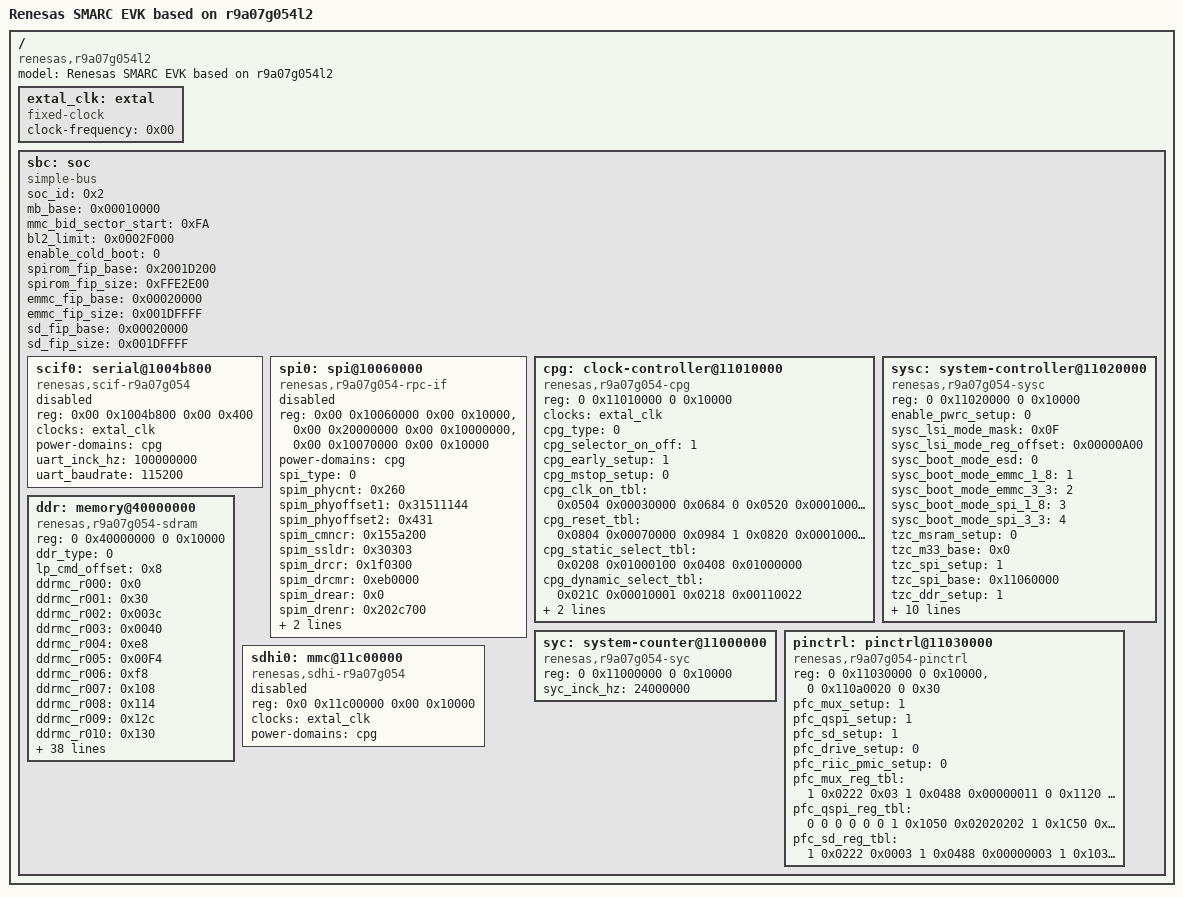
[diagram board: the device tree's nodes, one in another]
// SPDX-License-Identifier: (GPL-2.0-only OR BSD-2-Clause)
/*
 * Device Tree Source for the RZ/V2L SMARC EVK board
 *
 * Copyright (C) 2025 Renesas Electronics Corp.
 */

/dts-v1/;

/ {
	compatible = "renesas,r9a07g054l2", "renesas,r9a07g054";
	model = "Renesas SMARC EVK based on r9a07g054l2";
	#address-cells = <2>;
	#size-cells = <2>;

	/* clock can be either from exclk or crystal oscillator (XIN/XOUT) */
	extal_clk: extal {
		compatible = "fixed-clock";
		#clock-cells = <0x00>;
		clock-frequency = <0x00>;
		phandle = <0x03>;
	};

	sbc: soc {
		compatible = "simple-bus";
		soc_id = <0x2>;
		mb_base = <0x00010000>;
		mmc_bid_sector_start = <0xFA>;
		bl2_limit = <0x0002F000>;
		enable_cold_boot = <0>;
		spirom_fip_base = <0x2001D200>;
		spirom_fip_size = <0xFFE2E00>;
		emmc_fip_base = <0x00020000>;
		emmc_fip_size = <0x001DFFFF>;
		sd_fip_base = <0x00020000>;
		sd_fip_size = <0x001DFFFF>;
		#address-cells = <0x02>;
		#size-cells = <0x02>;
		ranges;

		scif0: serial@1004b800 {
			compatible = "renesas,scif-r9a07g054";
			reg = <0x00 0x1004b800 0x00 0x400>;
			interrupt-names = "eri", "rxi", "txi", "bri", "dri", "tei";
			clocks = <&extal_clk>;
			clock-names = "fck";
			power-domains = <&cpg>;
			status = "disabled";

			uart_inck_hz = <100000000>;
			uart_baudrate = <115200>;
		};

		spi0: spi@10060000 {
			compatible = "renesas,r9a07g054-rpc-if", "renesas,rzg2l-rpc-if";
			reg = <0x00 0x10060000 0x00 0x10000>,
			      <0x00 0x20000000 0x00 0x10000000>,
			      <0x00 0x10070000 0x00 0x10000>;
			reg-names = "regs", "dirmap", "wbuf";
			power-domains = <&cpg>;
			#address-cells = <1>;
			#size-cells = <0>;
			status = "disabled";

			/* SPI type
			 * [0] = SPI Multi IO
			 * [1] = XSPI
			 */
			spi_type = <0>;

			/* SPI Multi IO specific settings */
			spim_phycnt = <0x260>;
			spim_phyoffset1 = <0x31511144>;
			spim_phyoffset2 = <0x431>;
			spim_cmncr = <0x155a200>;
			spim_ssldr = <0x30303>;
			spim_drcr = <0x1f0300>;
			spim_drcmr = <0xeb0000>;
			spim_drear = <0x0>;
			spim_drenr = <0x202c700>;
			spim_drdmcr = <0x9>;
			spim_drdrenr = <0x0>;
		};

		cpg: clock-controller@11010000 {
			compatible = "renesas,r9a07g054-cpg";
			reg = <0 0x11010000 0 0x10000>;
			clocks = <&extal_clk>;
			clock-names = "extal";
			#clock-cells = <2>;
			#reset-cells = <1>;
			#power-domain-cells = <0>;

			cpg_type = <0>;
			cpg_selector_on_off = <1>;
			cpg_early_setup = <1>;
			cpg_mstop_setup = <0>;

			cpg_clk_on_tbl = <
				0x0504 0x00030000
				0x0684
				0

				0x0520 0x00010000
				0x06A0
				0

				0x052C 0x00030003
				0x06AC
				0

				0x0534 0x00060000
				0x06B4
				0

				0x0538 0x00010000
				0x06B8
				0

				0x053C 0x00010000
				0x06BC
				0

				0x0540 0x00010000
				0x06C0
				0

				0x0544 0x000F0000
				0x06C4
				0

				0x0548 0x003C0000
				0x06C8
				0


				0x054C 0x00030000
				0x06CC
				0

				0x0550 0x00030003
				0x06D0
				0

				0x0554 0x00ff00ff
				0x06D4
				0

				0x0558 0x00070000
				0x06D8
				0

				0x055C 0x00030000
				0x06DC
				0

				0x0560 0x00010001
				0x06E0
				0

				0x0564 0x001f0000
				0x06E4
				0

				0x0568 0x003f0000
				0x06E8
				0

				0x056C 0x00030000
				0x06EC
				0

				0x0570 0x00ff0000
				0x06F0
				0

				0x0574 0x00010000
				0x06F4
				0

				0x0578 0x000f0000
				0x06F8
				0

				0x057C 0x00030000
				0x06FC
				0

				0x0580 0x000f0000
				0x0700
				0

				0x0584 0x001f0001
				0x0704
				0

				0x0588 0x00030000
				0x0708
				0

				0x058C 0x00010000
				0x070C
				0

				0x0590 0x00070000
				0x0710
				0

				0x0594 0x00010000
				0x0714
				0

				0x0598 0x00010001
				0x0718
				0

				0x05A8 0x00030000
				0x0728
				0

				0x05AC 0x00010000
				0x072C
				0
			>;

			cpg_reset_tbl = <
				0x0804 0x00070000
				0x0984
				1

				0x0820 0x00010000
				0x09A0
				1

				0x082C 0x00030003
				0x09AC
				1

				0x0834 0x00060000
				0x09B4
				1

				0x0838 0x00010000
				0x09B8
				1

				0x083C 0x00010000
				0x09BC
				1

				0x0840 0x00010000
				0x09C0
				1

				0x0844 0x000f0000
				0x09C4
				1

				0x0848 0x00060000
				0x09C8
				1

				0x084C 0x007F0000
				0x09CC
				1

				0x0850 0x00010001
				0x09D0
				1

				0x0854 0x00030003
				0x09D4
				1

				0x0858 0x00070000
				0x09D8
				1

				0x085C 0x00030000
				0x09DC
				1

				0x0860 0x00030003
				0x09E0
				1

				0x0864 0x00070000
				0x09E4
				1

				0x0868 0x00070000
				0x09E8
				1

				0x086C 0x00010000
				0x09EC
				1

				0x0870 0x000f0000
				0x09F0
				1

				0x0874 0x00010000
				0x09F4
				1

				0x0878 0x000f0000
				0x09F8
				1

				0x087C 0x00030000
				0x09FC
				1

				0x0880 0x000f0000
				0x0A00
				1

				0x0884 0x001f0001
				0x0A04
				1

				0x0888 0x00030000
				0x0A08
				1

				0x088C 0x00010000
				0x0A0C
				1

				0x0890 0x00070000
				0x0A10
				1

				0x0894 0x00030000
				0x0A14
				1

				0x0898 0x00070007
				0x0A18
				1

				0x08A8 0x00030000
				0x0A28
				1

				0x08AC 0x00010000
				0x0A2C
				1
			>;

			cpg_static_select_tbl = <
				0x0208 0x01000100
				0x0408 0x01000000
			>;

			cpg_dynamic_select_tbl = <
				0x021C 0x00010001
				0x0218 0x00110022
			>;

			cpg_pll_tbl = <
				0x0010 0x00010001
				0x0014 0xFAE13203
				0x0018 0x00081000
				0x001C 0x00000011

				0x0020 0x00010001
				0x0024 0x00003e83
				0x0028 0x00082D02
				0x002C 0x00000011
			>;
		};

		sysc: system-controller@11020000 {
			compatible = "renesas,r9a07g054-sysc";
			reg = <0 0x11020000 0 0x10000>;

			enable_pwrc_setup					= <0>;
			sysc_lsi_mode_mask 			= <0x0F>;
			sysc_lsi_mode_reg_offset	= <0x00000A00>;
			sysc_boot_mode_esd 			= <0>;
			sysc_boot_mode_emmc_1_8 	= <1>;
			sysc_boot_mode_emmc_3_3 	= <2>;
			sysc_boot_mode_spi_1_8 		= <3>;
			sysc_boot_mode_spi_3_3 		= <4>;

			/* Security control. */
			tzc_msram_setup = <0>;
			tzc_m33_base	= <0x0>;	// Not used
			tzc_spi_setup	= <1>;
			tzc_spi_base	= <0x11060000>;
			tzc_ddr_setup	= <1>;
			tzc_ddr00_base	= <0x11070000>;
			tzc_ddr01_base	= <0x0>;	// Not used
			tzc_ddr10_base	= <0x0>;	// Not used
			tzc_ddr11_base	= <0x0>;	// Not used
			tzc_pci_setup	= <0>;
			tzc_pci_base	= <0x0>;	// Not used
			tzc_r8_setup	= <0>;
			tzc_r8_base		= <0x0>;	// Not used

			sys_acctl = <
				0x00000000 0x00BB00BB 0x00AAAA88
				0x00000004 0xBBBBBBBB 0xAAAAAAAA
				0x00000008 0x00BBBBBB 0x00AAAAAA
				0x0000000C 0x00BBBBBB 0x00AAAAAA
				0x00000010 0x0B0B00BB 0x0A0A00AA
				0x00000014 0x00000000 0x00000000
				0x00000100 0x0000000F 0x00000008
				0x00000104 0x3FFF3CFF 0x0800C0AA
				0x00000108 0x00FFCFFF 0x00000002
				0x0000010C 0x3FFF3FFF 0x00000000
				0x00000110 0xFFFF0FFF 0x00000000
				0x00000114 0x00000033 0x00000000
				0x00000118 0x0000000F 0x00000000
				0x0000011C 0x0000000C 0x00000008
				0x00000120 0x0000000F 0x00000000
				0x00000124 0x00000000 0x00000000
				0x00000128 0x00000003 0x00000000
				0x0000012C 0x00000000 0x00000000
				0x00000130 0x00000003 0x00000000
				0x00000134 0x00000003 0x00000000
				0x00000138 0x00000003 0x00000000
				0x0000013C 0x00000000 0x00000000
			>;
		};

		syc: system-counter@11000000 {
			compatible = "renesas,r9a07g054-syc";
			reg = <0 0x11000000 0 0x10000>;

			syc_inck_hz = <24000000>;
		};

		pinctrl: pinctrl@11030000 {
			compatible = "renesas,r9a07g054-pinctrl";
			reg = <0 0x11030000 0 0x10000>, <0 0x110a0020 0 0x30>;

			pfc_mux_setup		= <1>;
			pfc_qspi_setup		= <1>;
			pfc_sd_setup		= <1>;
			pfc_drive_setup		= <0>;
			pfc_riic_pmic_setup	= <0>;

			pfc_mux_reg_tbl = <
				1 0x0222 0x03
				1 0x0488 0x00000011
				0 0x1120 0x00000101
				0 0x1D10 0x00000000
				0 0x1510 0x00000101

				1 0x0223 0x03
				1 0x048C 0x00000011
				0 0x1128 0x00000101
				0 0x1D18 0x00000000
				0 0x1518 0x00000101

				1 0x0236 0x03
				1 0x04D8 0x00000011
				0 0x11B0 0x00000101
				0 0x1DB0 0x00000000
				0 0x15B0 0x00000101

				1 0x0237 0x07
				1 0x04DC 0x00000111
				0 0x11B8 0x00010101
				0 0x1DB8 0x00000000
				0 0x15B8 0x00010101
			>;

			pfc_qspi_reg_tbl = <
				0 0 0
				0 0 0
				1 0x1050 0x02020202
				1 0x1C50 0x00000000
				1 0x1450 0x01010101

				0 0 0
				0 0 0
				1 0x1058 0x02020202
				1 0x1C58 0x00000000
				1 0x1458 0x01010101

				0 0 0
				0 0 0
				1 0x1060 0x00020202
				1 0x1C60 0x00000000
				1 0x1460 0x00010000
			>;

			pfc_sd_reg_tbl = <
				1 0x0222 0x0003
				1 0x0488 0x00000003
				1 0x1030 0x00020202
				1 0x1C30 0x00000000
				1 0x1430 0x00010101
				1 0x1830 0x00000100

				0 0 0
				0 0 0
				1 0x1038 0x02020202
				1 0x1C38 0x00000000
				1 0x1438 0x01010101
				1 0x1838 0x01010101

				1 0x0223 0x0003
				1 0x048C 0x00000003

				1 0x1040 0x00000202
				1 0x1C40 0x00000000
				1 0x1440 0x00000101
				1 0x1840 0x00000100

				0 0 0
				0 0 0
				1 0x1048 0x02020202
				1 0x1C48 0x00000000
				1 0x1448 0x01010101
				1 0x1848 0x01010101
			>;
		};

		ddr: memory@40000000 {
			compatible = "renesas,r9a07g054-sdram";
			reg = <0 0x40000000 0 0x10000>;

			/* DDR type
			 * [0] = DDR4
			 * [1] = LPDDR4
			 */
			ddr_type = <0>;

			lp_cmd_offset = <0x8>;

			ddrmc_r000 = <0x0>;
			ddrmc_r001 = <0x30>;
			ddrmc_r002 = <0x003c>;
			ddrmc_r003 = <0x0040>;
			ddrmc_r004 = <0xe8>;
			ddrmc_r005 = <0x00F4>;
			ddrmc_r006 = <0xf8>;
			ddrmc_r007 = <0x108>;
			ddrmc_r008 = <0x114>;
			ddrmc_r009 = <0x12c>;
			ddrmc_r010 = <0x130>;
			ddrmc_r011 = <0x138>;
			ddrmc_r012 = <0x13c>;
			ddrmc_r013 = <0x140>;
			ddrmc_r014 = <0x144>;
			ddrmc_r015 = <0x158>;
			ddrmc_r016 = <0x15c>;
			ddrmc_r017 = <0x160>;
			ddrmc_r018 = <0x164>;
			ddrmc_r019 = <0x022C>;
			ddrmc_r020 = <0x230>;
			ddrmc_r021 = <0x0260>;
			ddrmc_r022 = <0x0264>;
			ddrmc_r023 = <0x280>;
			ddrmc_r024 = <0x284>;
			ddrmc_r025 = <0x2d8>;
			ddrmc_r026 = <0x2dc>;
			ddrmc_r027 = <0x74c>;
			ddrmc_r028 = <0x0768>;
			ddrmc_r029 = <0x774>;
			ddrmc_r039 = <0x07A4>;
			ddrmc_r040 = <0x07A8>;
			ddrmc_r043 = <0x07B4>;
			ddrmc_r044 = <0x7b8>;

			swizzle_mc_tbl = <
				0x077C 0x00000B02
				0x0780 0x00000106
				0x0784 0x11131C0D
				0x0788 0x12001F15
				0x078C 0x1D19140E
				0x0790 0x17091B1A
				0x0794 0x0A10160C
				0x0798 0x0018051E
				0x079C 0x00000000
			>;

			mc_init_num = <507>;

			mc_init_tbl = <
				0x0 0xa00
				0x4 0x0
				0x8 0x0
				0xc 0x0
				0x10 0x0
				0x14 0x0
				0x18 0x0
				0x1c 0x0
				0x20 0x0
				0x24 0x0
				0x28 0x0
				0x2c 0x1000008
				0x30 0x100100
				0x34 0x27100
				0x38 0x61a80
				0x3c 0x9180255
				0x40 0x18180000
				0x44 0x5050404
				0x48 0x2806
				0x4c 0x602001c
				0x50 0x6001c0c
				0x54 0x180806
				0x58 0x400db60
				0x5c 0x30305
				0x60 0xc0c
				0x64 0x3180101
				0x68 0xc0c
				0x6c 0x10101
				0x74 0x0
				0x78 0x0
				0x7c 0x40301
				0x80 0x1b8
				0x84 0x1860
				0x88 0x5
				0x8c 0x140005
				0x90 0x1c00255
				0x94 0x1c0
				0x98 0x1000201
				0x9c 0x80104002
				0xa0 0x0
				0xa4 0x40000
				0xa8 0x0
				0xac 0x61800
				0xb0 0x7d0
				0xb4 0x61800
				0xb8 0x61800
				0xbc 0x61800
				0xc0 0x0
				0xc4 0x1000000
				0xc8 0x0
				0xcc 0x0
				0xd0 0x0
				0xd4 0x0
				0xd8 0x0
				0xdc 0x0
				0xe0 0x0
				0xe4 0x21210000
				0xe8 0x7000000
				0xec 0xe010a09
				0xf0 0x3002f
				0xf4 0x10004
				0xf8 0x800
				0xfc 0x0
				0x100 0x0
				0x104 0x0
				0x108 0x100
				0x10c 0x200
				0x110 0x1000
				0x114 0x0
				0x118 0x0
				0x128 0x214
				0x12c 0x101
				0x130 0x0
				0x134 0x214
				0x138 0x101
				0x13c 0x0
				0x140 0x0
				0x144 0x0
				0x148 0x0
				0x14c 0x0
				0x150 0x0
				0x154 0x0
				0x158 0x80
				0x15c 0x80
				0x160 0x40f
				0x164 0x40f
				0x168 0x0
				0x16c 0x10100
				0x170 0x0
				0x174 0x0
				0x178 0x0
				0x17c 0x0
				0x180 0x0
				0x184 0x0
				0x188 0x0
				0x18c 0x0
				0x190 0x0
				0x194 0x1000200
				0x198 0x10801
				0x19c 0x0
				0x1a0 0x0
				0x1a4 0x0
				0x1a8 0x0
				0x1ac 0x0
				0x1b0 0x0
				0x1b4 0x0
				0x1b8 0x0
				0x1bc 0x0
				0x1c0 0x0
				0x1c4 0x0
				0x1c8 0x0
				0x1cc 0x0
				0x1d0 0x8
				0x1d4 0x6403e8
				0x1d8 0x0
				0x1dc 0x0
				0x1e0 0x0
				0x1e4 0x14110000
				0x1e8 0x80c18
				0x1ec 0xbebd03
				0x1f0 0xc350
				0x1f4 0x0
				0x1f8 0x2000400
				0x1fc 0x80
				0x200 0x10100
				0x204 0x10100
				0x208 0x1fff0000
				0x20c 0x3ff00
				0x210 0xffffffff
				0x214 0xffff00
				0x218 0xffff0a00
				0x21c 0x1010001
				0x220 0x1010101
				0x224 0x1030101
				0x228 0xc010000
				0x22c 0x1000000
				0x230 0x0
				0x234 0x10000
				0x238 0x0
				0x23c 0x1
				0x240 0x0
				0x244 0x0
				0x248 0x0
				0x24c 0x0
				0x250 0x0
				0x254 0x0
				0x258 0x0
				0x25c 0x0
				0x260 0x0
				0x264 0x0
				0x268 0x0
				0x26c 0x0
				0x270 0x0
				0x274 0x0
				0x278 0x0
				0x27c 0x0
				0x280 0x0
				0x284 0x0
				0x288 0x0
				0x28c 0x10000
				0x290 0x0
				0x294 0x800
				0x298 0x0
				0x29c 0x898
				0x2a0 0x3000000
				0x2a4 0x408
				0x2a8 0x0
				0x2ac 0x0
				0x2b0 0x0
				0x2b4 0x0
				0x2b8 0x0
				0x2bc 0x0
				0x2c0 0x0
				0x2c4 0x0
				0x2c8 0x0
				0x2cc 0x0
				0x2d0 0x0
				0x2d4 0x6060800
				0x2d8 0x1000001
				0x2dc 0x1030000
				0x2e0 0x3000302
				0x2e4 0x0
				0x2e8 0x80801
				0x2ec 0x80801
				0x2f0 0x70601
				0x2f4 0x80801
				0x2f8 0x0
				0x2fc 0xfffff
				0x300 0xffffffff
				0x304 0xf000f
				0x308 0x0
				0x30c 0x30fffff
				0x310 0xffffffff
				0x314 0xf000f
				0x318 0x0
				0x31c 0x30fffff
				0x320 0xffffffff
				0x324 0xf000f
				0x328 0x0
				0x32c 0x30fffff
				0x330 0xffffffff
				0x334 0xf000f
				0x338 0x0
				0x33c 0x30fffff
				0x340 0xffffffff
				0x344 0xf000f
				0x348 0x0
				0x34c 0x30fffff
				0x350 0xffffffff
				0x354 0xf000f
				0x358 0x0
				0x35c 0x30fffff
				0x360 0xffffffff
				0x364 0xf000f
				0x368 0x0
				0x36c 0x30fffff
				0x370 0xffffffff
				0x374 0xf000f
				0x378 0x0
				0x37c 0x30fffff
				0x380 0xffffffff
				0x384 0xf000f
				0x388 0x0
				0x38c 0x30fffff
				0x390 0xffffffff
				0x394 0xf000f
				0x398 0x0
				0x39c 0x30fffff
				0x3a0 0xffffffff
				0x3a4 0xf000f
				0x3a8 0x0
				0x3ac 0x30fffff
				0x3b0 0xffffffff
				0x3b4 0xf000f
				0x3b8 0x0
				0x3bc 0x30fffff
				0x3c0 0xffffffff
				0x3c4 0xf000f
				0x3c8 0x0
				0x3cc 0x30fffff
				0x3d0 0xffffffff
				0x3d4 0xf000f
				0x3d8 0x0
				0x3dc 0x30fffff
				0x3e0 0xffffffff
				0x3e4 0xf000f
				0x3e8 0x0
				0x3ec 0x30fffff
				0x3f0 0xffffffff
				0x3f4 0xf000f
				0x3f8 0x0
				0x3fc 0xfffff
				0x400 0xffffffff
				0x404 0xf000f
				0x408 0x0
				0x40c 0x30fffff
				0x410 0xffffffff
				0x414 0xf000f
				0x418 0x0
				0x41c 0x30fffff
				0x420 0xffffffff
				0x424 0xf000f
				0x428 0x0
				0x42c 0x30fffff
				0x430 0xffffffff
				0x434 0xf000f
				0x438 0x0
				0x43c 0x30fffff
				0x440 0xffffffff
				0x444 0xf000f
				0x448 0x0
				0x44c 0x30fffff
				0x450 0xffffffff
				0x454 0xf000f
				0x458 0x0
				0x45c 0x30fffff
				0x460 0xffffffff
				0x464 0xf000f
				0x468 0x0
				0x46c 0x30fffff
				0x470 0xffffffff
				0x474 0xf000f
				0x478 0x0
				0x47c 0x30fffff
				0x480 0xffffffff
				0x484 0xf000f
				0x488 0x0
				0x48c 0x30fffff
				0x490 0xffffffff
				0x494 0xf000f
				0x498 0x0
				0x49c 0x30fffff
				0x4a0 0xffffffff
				0x4a4 0xf000f
				0x4a8 0x0
				0x4ac 0x30fffff
				0x4b0 0xffffffff
				0x4b4 0xf000f
				0x4b8 0x0
				0x4bc 0x30fffff
				0x4c0 0xffffffff
				0x4c4 0xf000f
				0x4c8 0x0
				0x4cc 0x30fffff
				0x4d0 0xffffffff
				0x4d4 0xf000f
				0x4d8 0x0
				0x4dc 0x30fffff
				0x4e0 0xffffffff
				0x4e4 0xf000f
				0x4e8 0x0
				0x4ec 0x30fffff
				0x4f0 0xffffffff
				0x4f4 0xf000f
				0x4f8 0x0
				0x4fc 0xfffff
				0x500 0xffffffff
				0x504 0xf000f
				0x508 0x0
				0x50c 0x30fffff
				0x510 0xffffffff
				0x514 0xf000f
				0x518 0x0
				0x51c 0x30fffff
				0x520 0xffffffff
				0x524 0xf000f
				0x528 0x0
				0x52c 0x30fffff
				0x530 0xffffffff
				0x534 0xf000f
				0x538 0x0
				0x53c 0x30fffff
				0x540 0xffffffff
				0x544 0xf000f
				0x548 0x0
				0x54c 0x30fffff
				0x550 0xffffffff
				0x554 0xf000f
				0x558 0x0
				0x55c 0x30fffff
				0x560 0xffffffff
				0x564 0xf000f
				0x568 0x0
				0x56c 0x30fffff
				0x570 0xffffffff
				0x574 0xf000f
				0x578 0x0
				0x57c 0x30fffff
				0x580 0xffffffff
				0x584 0xf000f
				0x588 0x0
				0x58c 0x30fffff
				0x590 0xffffffff
				0x594 0xf000f
				0x598 0x0
				0x59c 0x30fffff
				0x5a0 0xffffffff
				0x5a4 0xf000f
				0x5a8 0x0
				0x5ac 0x30fffff
				0x5b0 0xffffffff
				0x5b4 0xf000f
				0x5b8 0x0
				0x5bc 0x30fffff
				0x5c0 0xffffffff
				0x5c4 0xf000f
				0x5c8 0x0
				0x5cc 0x30fffff
				0x5d0 0xffffffff
				0x5d4 0xf000f
				0x5d8 0x0
				0x5dc 0x30fffff
				0x5e0 0xffffffff
				0x5e4 0xf000f
				0x5e8 0x0
				0x5ec 0x30fffff
				0x5f0 0xffffffff
				0x5f4 0xf000f
				0x5f8 0x0
				0x5fc 0xfffff
				0x600 0xffffffff
				0x604 0xf000f
				0x608 0x0
				0x60c 0x30fffff
				0x610 0xffffffff
				0x614 0xf000f
				0x618 0x0
				0x61c 0x30fffff
				0x620 0xffffffff
				0x624 0xf000f
				0x628 0x0
				0x62c 0x30fffff
				0x630 0xffffffff
				0x634 0xf000f
				0x638 0x0
				0x63c 0x30fffff
				0x640 0xffffffff
				0x644 0xf000f
				0x648 0x0
				0x64c 0x30fffff
				0x650 0xffffffff
				0x654 0xf000f
				0x658 0x0
				0x65c 0x30fffff
				0x660 0xffffffff
				0x664 0xf000f
				0x668 0x0
				0x66c 0x30fffff
				0x670 0xffffffff
				0x674 0xf000f
				0x678 0x0
				0x67c 0x30fffff
				0x680 0xffffffff
				0x684 0xf000f
				0x688 0x0
				0x68c 0x30fffff
				0x690 0xffffffff
				0x694 0xf000f
				0x698 0x0
				0x69c 0x30fffff
				0x6a0 0xffffffff
				0x6a4 0xf000f
				0x6a8 0x0
				0x6ac 0x30fffff
				0x6b0 0xffffffff
				0x6b4 0xf000f
				0x6b8 0x0
				0x6bc 0x30fffff
				0x6c0 0xffffffff
				0x6c4 0xf000f
				0x6c8 0x0
				0x6cc 0x30fffff
				0x6d0 0xffffffff
				0x6d4 0xf000f
				0x6d8 0x0
				0x6dc 0x30fffff
				0x6e0 0xffffffff
				0x6e4 0xf000f
				0x6e8 0x0
				0x6ec 0x30fffff
				0x6f0 0xffffffff
				0x6f4 0xf000f
				0x6f8 0x4000000
				0x6fc 0x4040404
				0x700 0x4040404
				0x704 0x4040404
				0x708 0x40404
				0x70c 0x3030064
				0x710 0x3030303
				0x714 0x3030303
				0x718 0x3030303
				0x71c 0x10303
				0x720 0x2020064
				0x724 0x2020202
				0x728 0x2020202
				0x72c 0x2020202
				0x730 0x20202
				0x734 0x1010064
				0x738 0x1010101
				0x73c 0x1010101
				0x740 0x1010101
				0x744 0x30101
				0x748 0x64
				0x74c 0x6
				0x750 0x7d0
				0x754 0x32
				0x758 0x200
				0x75c 0x200
				0x760 0x0
				0x764 0x0
				0x768 0x30b0205
				0x76c 0x200308
				0x770 0x0
				0x774 0xa000202
				0x778 0xc000a
				0x77c 0x0
				0x780 0x0
				0x784 0x0
				0x788 0x0
				0x78c 0x0
				0x790 0x0
				0x794 0x0
				0x798 0x0
				0x79c 0x0
				0x7a0 0xf
				0x7a4 0x37204e2
				0x7a8 0x57630bb8
				0x7ac 0x2828
				0x7b0 0x3c22
				0x7b4 0x102611
				0x7b8 0x0
				0x7bc 0x0
				0x7c0 0x0
				0x7c4 0x0
				0x7c8 0x0
				0x7cc 0x0
				0x7d0 0x0
				0x7d4 0x0
				0x7d8 0x0
				0x7dc 0x0
				0x7e0 0x0
				0x7e4 0x0
				0x7e8 0x0
				0x7ec 0x0
				0x7f0 0x0
				0x7f4 0x0
				0x7f8 0x0
			>;

			swizzle_phy_tbl = <
				0x12C 0x00000000
				0x0A8 0x14001816
				0x12C 0x00000001
				0x0A8 0x010D0608
				0x12C 0x00000002
				0x0A8 0x02190403
				0x12C 0x00000003
				0x0A8 0x1705150B
				0x12C 0x00000004
				0x0A8 0x13121110
				0x12C 0x00000005
				0x0A8 0x07090F0E
				0x12C 0x00000006
				0x0A8 0x1A1D0A1B
				0x12C 0x00000007
				0x0A8 0x001E1C0C
			>;

			mc_phy_settings_tbl = <
				0x7a8 0x57630bb8
				0x7ac 0x2828
				0x7b0 0x3c22
				0x7b4 0x102611
			>;

			mc_odt_pins_tbl = <
				0x00000001
				0x00000000
				0x00000000
				0x00000000
			>;

			mc_mr1_tbl = <
				0x00000706
				0x00000100
			>;

			mc_mr2_tbl = <
				0x00000E00
				0x00000000
			>;

			mc_mr5_tbl = <
				0x000001C0
				0x000001C0
			>;

			mc_mr6_tbl = <
				0x0000007F
				0x0000000F
			>;
		};

		sdhi0: mmc@11c00000 {
			compatible = "renesas,sdhi-r9a07g054",
				     "renesas,rcar-gen3-sdhi";
			reg = <0x0 0x11c00000 0x00 0x10000>;
			clock-names = "core", "clkh", "cd", "aclk";
			clocks = <&extal_clk>;
			power-domains = <&cpg>;
			status = "disabled";
		};
	};
};
